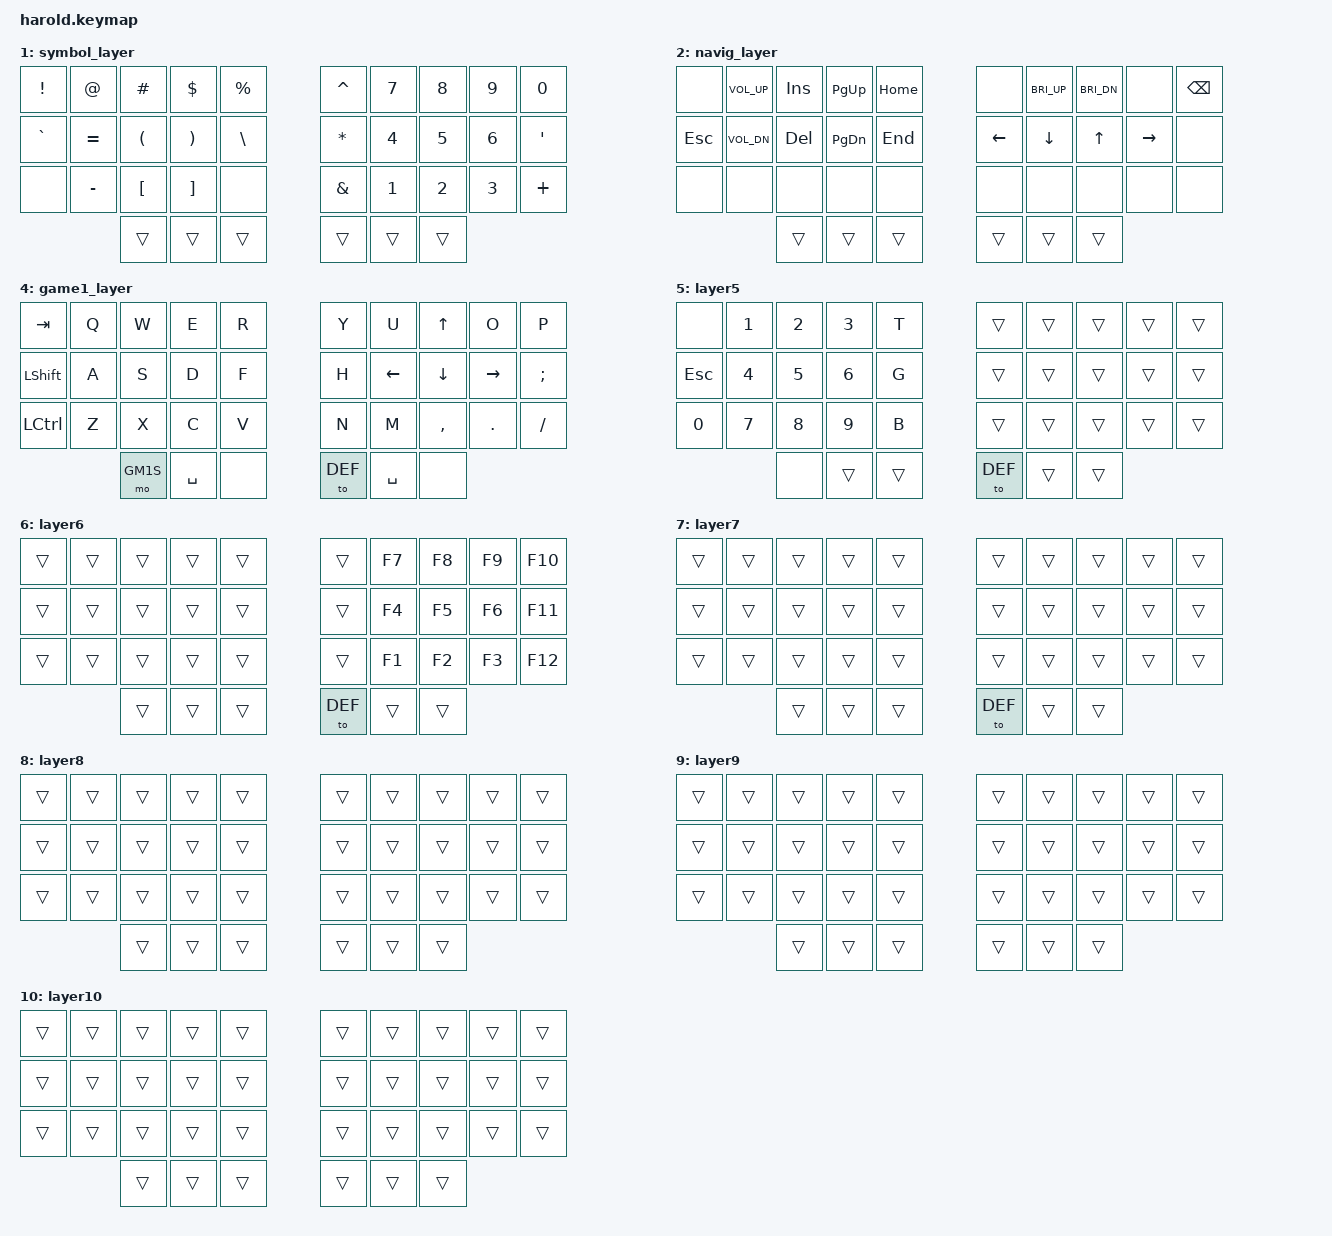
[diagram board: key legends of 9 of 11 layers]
// Copyright (c) 2022 The ZMK Contributors
// SPDX-License-Identifier: MIT

#include <behaviors.dtsi>
#include <dt-bindings/zmk/keys.h>
#include <dt-bindings/zmk/bt.h>

// Home row mods macro
#define HRML(k1,k2) &ht LALT  k1  &ht LCTRL k2
#define HRMR(k1,k2) &ht RCTRL k1  &ht RALT  k2

#define HTWN(k1)    &htwin LGUI k1

// Bluetooth Profile Selection shortcut
#define BTSL(X)      &bt BT_SEL X

// Some handy aliases
#define WQUIT        LA(F4)     // Windows Quit
#define TMUX_MOD     LC(SPACE)  // TMUX Modifier

// Layer Mnemonics
#define DEF   0   // Default
#define SYM   1   // Symbols
#define NAV   2   // Navigation + Media
#define CFG   3   // Misc/Settings
#define GM1   4   // Gaming 1
#define GM1S  5   // Gaming 1 Super-Layer
#define FKEY  6   // F-Key layer, OneShot w/ Sticky Keys

// Emoji Key Defines

// Key positions (For combo keys etc)
//  ╭────┬────┬────┬────┬────╮   ╭────┬────┬────┬────┬────╮
//  │  0 │  1 │  2 │  3 │  4 │   │  5 │  6 │  7 │  8 │  9 │
//  ├────┼────┼────┼────┼────┤   ├────┼────┼────┼────┼────┤
//  │ 10 │ 11 │ 12 │ 13 │ 14 │   │ 15 │ 16 │ 17 │ 18 │ 19 │
//  ├────┼────┼────┼────┼────┤   ├────┼────┼────┼────┼────┤
//  │ 20 │ 21 │ 22 │ 23 │ 24 │   │ 25 │ 26 │ 27 │ 28 │ 29 │
//  ╰────┴────┼────┼────┼────┤   ├────┼────┼────┼────┴────╯
//            │ 30 │ 31 │ 32 │   │ 33 │ 34 │ 35 │
//            ╰────┴────┴────╯   ╰────┴────┴────╯

/ {
    combos {
        compatible = "zmk,combos";
        combo_game1 {
            timeout-ms = <50>;
            key-positions = <34 35>;
            bindings = <&to GM1>;
        };
    };

    behaviors {
        ht: hold_tap {
            label = "hold_tap";
            compatible = "zmk,behavior-hold-tap";
            #binding-cells = <2>;
            flavor = "balanced";
            tapping-term-ms = <350>;
            quick-tap-ms = <150>;
            global-quick-tap;
            bindings = <&kp>, <&kp>;
        };


        // Slower hold-tap for the windows key because it keeps triggering
        // So annoying ...
        htwin: hold_tap_win {
            label = "hold_tap_win";
            compatible = "zmk,behavior-hold-tap";
            #binding-cells = <2>;
            flavor = "balanced";

            tapping-term-ms = <400>;
            quick-tap-ms = <200>;
            global-quick-tap;
            bindings = <&kp>, <&kp>;
        };

        // TODO change this into some macro that sends
        // the tmux mode code (Ctrl+Spc) if it tap-held
        // for every subsequent key pressed
        td_tm: tmux_modifier {
            label = "tmux-tap-dance";
            compatible = "zmk,behavior-tap-dance";
            #binding-cells = <0>;
            bindings = <&mo NAV>, <&kp TMUX_MOD>;
        };

        td_cw: caps_word {
            label = "capsword-tap-dance";
            compatible = "zmk,behavior-tap-dance";
            #binding-cells = <0>;
            bindings = <&kp LSHIFT>, <&caps_word>;
        };
    };

    conditional_layers {
        compatible = "zmk,conditional-layers";
        tri_layer {
            if-layers = <SYM NAV>;
            then-layer = <CFG>;
        };
    };

    keymap {
        compatible = "zmk,keymap";
        // Layer 0
        // Note HomeRow Mods on Index/Middle finger for Ctrl/Alt respectively
        // Note Hold-Tap Win/Super key on pinky; originally on home row, but kept triggering
        default_layer {
            bindings = <
        //╭──────────┬──────────┬──────────┬──────────┬──────────╮   ╭──────────┬──────────┬──────────┬──────────┬──────────╮
        //│  Q       │  W       │  E       │  R       │  T       │   │  Y       │  U       │  I       │  O       │  P       │
            &kp Q      &kp W      &kp E      &kp R      &kp T          &kp Y      &kp U      &kp I      &kp O      &kp P
        //├──────────┼──────────┼──────────┼──────────┼──────────┤   ├──────────┼──────────┼──────────┼──────────┼──────────┤
        //│  A       │  S       │  D       │  F       │  G       │   │  H       │  J       │  K       │  L       │ ; :      │
            &kp A      &kp S     HRML(D,         F)     &kp G          &kp H      HRMR(J,        K)     &kp L      &kp SEMI
        //├──────────┼──────────┼──────────┼──────────┼──────────┤   ├──────────┼──────────┼──────────┼──────────┼──────────┤
        //│  Z       │  X       │  C       │  V       │  B       │   │  N       │  M       │ , <      │ . >      │ / ?      │
            HTWN(Z)    &kp X      &kp C      &kp V      &kp B          &kp N      &kp M      &kp COMMA  &kp DOT    HTWN(FSLH)
        //╰──────────┴──────────┼──────────┼──────────┼──────────┤   ├──────────┼──────────┼──────────┼──────────┴──────────╯
                                  &td_tm     &td_cw     &kp TAB        &kp RET    &kp SPACE  &mo SYM
        //                      ╰──────────┴──────────┴──────────╯   ╰──────────┴──────────┴──────────╯
            >;
        };

        // Layer 1: SYM
        symbol_layer {
            bindings = <
        //╭──────────┬──────────┬──────────┬──────────┬──────────╮   ╭──────────┬──────────┬──────────┬──────────┬──────────╮
        //│  !       │  @       │  #       │  $       │  %       │   │  ^       │  7       │  8       │  9       │  0       │
            &kp EXCL   &kp AT     &kp HASH   &kp DLLR   &kp PRCNT      &kp CARET  &kp N7     &kp N8     &kp N9     &kp N0
        //├──────────┼──────────┼──────────┼──────────┼──────────┤   ├──────────┼──────────┼──────────┼──────────┼──────────┤
        //│  `/~     │  =       │  (       │  )       │   \ |    │   │  *       │  4       │  5       │  6       │  ' "     │
            &kp GRAVE  &kp EQUAL  &kp LPAR   &kp RPAR   &kp BSLH       &kp STAR   &kp N4     &kp N5     &kp N6     &kp SQT
        //├──────────┼──────────┼──────────┼──────────┼──────────┤   ├──────────┼──────────┼──────────┼──────────┼──────────┤
        //│  (blank) │  - _     │  [ {     │  ] }     │          │   │  &       │  1       │  2       │  3       │  +       │
            &none      &kp MINUS  &kp LBKT   &kp RBKT   &none          &kp AMPS   &kp N1     &kp N2     &kp N3     &kp PLUS
        //╰──────────┴──────────┼──────────┼──────────┼──────────┤   ├──────────┼──────────┼──────────┼──────────┴──────────╯
                                  &trans     &trans     &trans         &trans     &trans     &trans
        //                      ╰──────────┴──────────┴──────────╯   ╰──────────┴──────────┴──────────╯
            >;
        };

        // Layer 2: NAV and Media
        navig_layer {
            bindings = <
        //╭──────────┬────────────┬──────────┬──────────┬──────────╮   ╭──────────┬───────────┬──────────┬──────────┬──────────╮
        //│          │  Vol+      │  Ins     │  PgUp    │  Home    │   │          │ Bright+   │ Bright-  │          │  BKSPACE │
            &none      &kp C_VOL_UP  &kp INS   &kp PG_UP  &kp HOME       &none      &kp C_BRI_UP &kp C_BRI_DN &none   &kp BSPC
        //├──────────┼────────────┼──────────┼──────────┼──────────┤   ├──────────┼───────────┼──────────┼──────────┼──────────┤
        //│  ESC     │  Vol-      │  Del     │  PgDn    │  End     │   │  LEFT    │  DOWN     │  UP      │  RIGHT   │          │
            &kp ESC    &kp C_VOL_DN &kp DEL    &kp PG_DN  &kp END        &kp LEFT   &kp DOWN    &kp UP     &kp RIGHT  &none     
        //├──────────┼────────────┼──────────┼──────────┼──────────┤   ├──────────┼───────────┼──────────┼──────────┼──────────┤
        //│          │            │          │          │          │   │          │           │          │          │          │
            &none      &none        &none      &none      &none          &none      &none       &none      &none      &none     
        //╰──────────┴────────────┼──────────┼──────────┼──────────┤   ├──────────┼───────────┼──────────┼──────────┴──────────╯
                                    &trans     &trans     &trans         &trans     &trans      &trans
        //                        ╰──────────┴──────────┴──────────╯   ╰──────────┴───────────┴──────────╯
            >;
        };

        // Layer 3: CFG layer
        config_layer {
            bindings = <
        //╭──────────┬────────────┬──────────┬──────────┬──────────╮   ╭──────────┬──────────┬──────────┬──────────┬──────────╮
        //│          │            │          │          │          │   │          │          │          │          │          │
            &bootloader &none       &none      &kp WQUIT   &none        &none      &none      &none      &none      &bootloader
        //├──────────┼────────────┼──────────┼──────────┼──────────┤   ├──────────┼──────────┼──────────┼──────────┼──────────┤
        //│          │            │          │          │          │   │          │          │          │          │          │
            &none      &to GM1      &sl FKEY   &none      &none          &none      BTSL(3)    BTSL(4)    &bt BT_CLR &none
        //├──────────┼────────────┼──────────┼──────────┼──────────┤   ├──────────┼──────────┼──────────┼──────────┼──────────┤
        //│          │            │          │          │          │   │          │          │          │          │          │
            &none      &none        &none      &none      &none          &none      BTSL(0)     BTSL(1)   BTSL(2)
        //╰──────────┴────────────┼──────────┼──────────┼──────────┤   ├──────────┼──────────┼──────────┼──────────┴──────────╯
                                    &trans     &trans     &trans         &trans     &trans     &trans
        //                        ╰──────────┴──────────┴──────────╯   ╰──────────┴──────────┴──────────╯
            >;
        };

        // Layer 4: GM1 (Gaming 1) Layer.
        //   It's QWERTY but shifted 1 to the right and includes TAB, Shift, and Ctrl keys
        game1_layer {
            bindings = <
        //╭────────────┬──────────┬──────────┬──────────┬──────────╮   ╭──────────┬──────────┬──────────┬──────────┬──────────╮
        //│   TAB      │ Q        │  W       │  E       │  R       │   │  Y       │  U       │  UP      │  O       │  P       │
            &kp TAB     &kp Q       &kp W      &kp E      &kp R          &kp Y      &kp U      &kp UP     &kp O      &kp P
        //├────────────┼──────────┼──────────┼──────────┼──────────┤   ├──────────┼──────────┼──────────┼──────────┼──────────┤
        //│  SHIFT     │ A        │  S       │  D       │  F       │   │  H       │  LEFT    │  DOWN    │  RIGHT   │ ; :      │
            &kp LSHIFT  &kp A       &kp S      &kp D      &kp F          &kp H      &kp LEFT   &kp DOWN   &kp RIGHT  &kp SEMI
        //├────────────┼──────────┼──────────┼──────────┼──────────┤   ├──────────┼──────────┼──────────┼──────────┼──────────┤
        //│  CTRL      │ Z        │  X       │  C       │  V       │   │  N       │  M       │ , <      │ . >      │ / ?      │
            &kp LCTRL   &kp Z       &kp X      &kp C      &kp V          &kp N      &kp M      &kp COMMA  &kp DOT    &kp FSLH
        //╰────────────┴──────────┼──────────┼──────────┼──────────┤   ├──────────┼──────────┼──────────┼──────────┴──────────╯
                                    &mo GM1S   &kp SPC    &none          &to DEF    &kp SPC    &none
        //                        ╰──────────┴──────────┴──────────╯   ╰──────────┴──────────┴──────────╯
            >;
        };

        // Layer 5: GM1S Gaming 1 Super-Layer
        //   Enables extra keys while within GM1 layer
        //   i.e. Number Keys, T/G/B keys etc
        layer5 {
            bindings = <
        //╭──────────┬────────────┬──────────┬──────────┬──────────╮   ╭──────────┬──────────┬──────────┬──────────┬──────────╮
        //│          │      1     │      2   │      3   │     T    │   │          │          │          │          │          │
            &none      &kp N1       &kp N2     &kp N3     &kp T          &trans     &trans     &trans     &trans     &trans
        //├──────────┼────────────┼──────────┼──────────┼──────────┤   ├──────────┼──────────┼──────────┼──────────┼──────────┤
        //│          │      4     │      5   │      6   │     G    │   │          │          │          │          │          │
            &kp ESC    &kp N4       &kp N5     &kp N6     &kp G          &trans     &trans     &trans     &trans     &trans
        //├──────────┼────────────┼──────────┼──────────┼──────────┤   ├──────────┼──────────┼──────────┼──────────┼──────────┤
        //│      0   │      7     │      8   │      9   │     B    │   │          │          │          │          │          │
            &kp N0     &kp N7       &kp N8     &kp N9     &kp B          &trans     &trans     &trans     &trans     &trans
        //╰──────────┴────────────┼──────────┼──────────┼──────────┤   ├──────────┼──────────┼──────────┼──────────┴──────────╯
                                    &none      &trans     &trans         &to DEF    &trans     &trans
        //                        ╰──────────┴──────────┴──────────╯   ╰──────────┴──────────┴──────────╯
            >;
        };

        // Layer 6: FKEY Layer (One-Shot)
        //          At the moment, F-Keys CANNOT be combined with other combinations ...
        //          Maybe I'll fix the keymap to support that eventually
        layer6 {
            bindings = <
        //╭──────────┬────────────┬──────────┬──────────┬──────────╮   ╭──────────┬──────────┬──────────┬──────────┬──────────╮
        //│          │            │          │          │          │   │          │  F7      │  F8      │  F9      │  F10     │
            &trans     &trans       &trans     &trans     &trans         &trans     &kp F7     &kp F8     &kp F9     &kp F10
        //├──────────┼────────────┼──────────┼──────────┼──────────┤   ├──────────┼──────────┼──────────┼──────────┼──────────┤
        //│          │            │          │          │          │   │          │  F4      │  F5      │  F6      │  F11     │
            &trans     &trans       &trans     &trans     &trans         &trans     &kp F4     &kp F5     &kp F6     &kp F11
        //├──────────┼────────────┼──────────┼──────────┼──────────┤   ├──────────┼──────────┼──────────┼──────────┼──────────┤
        //│          │            │          │          │          │   │          │  F1      │  F2      │  F3      │  F12     │
            &trans     &trans       &trans     &trans     &trans         &trans     &kp F1     &kp F2     &kp F3     &kp F12
        //╰──────────┴────────────┼──────────┼──────────┼──────────┤   ├──────────┼──────────┼──────────┼──────────┴──────────╯
                                    &trans     &trans     &trans         &to DEF    &trans     &trans
        //                        ╰──────────┴──────────┴──────────╯   ╰──────────┴──────────┴──────────╯
            >;
        };

        // Layer 7: TBD
        layer7 {
            bindings = <
        //╭──────────┬────────────┬──────────┬──────────┬──────────╮   ╭──────────┬──────────┬──────────┬──────────┬──────────╮
        //│          │            │          │          │          │   │          │          │          │          │          │
            &trans     &trans       &trans     &trans     &trans         &trans     &trans     &trans     &trans     &trans
        //├──────────┼────────────┼──────────┼──────────┼──────────┤   ├──────────┼──────────┼──────────┼──────────┼──────────┤
        //│          │            │          │          │          │   │          │          │          │          │          │
            &trans     &trans       &trans     &trans     &trans         &trans     &trans     &trans     &trans     &trans
        //├──────────┼────────────┼──────────┼──────────┼──────────┤   ├──────────┼──────────┼──────────┼──────────┼──────────┤
        //│          │            │          │          │          │   │          │          │          │          │          │
            &trans     &trans       &trans     &trans     &trans         &trans     &trans     &trans     &trans     &trans
        //╰──────────┴────────────┼──────────┼──────────┼──────────┤   ├──────────┼──────────┼──────────┼──────────┴──────────╯
                                    &trans     &trans     &trans         &to DEF    &trans     &trans
        //                        ╰──────────┴──────────┴──────────╯   ╰──────────┴──────────┴──────────╯
            >;
        };

        // Layer 8: TBD
        layer8 {
            bindings = <
        //╭──────────┬────────────┬──────────┬──────────┬──────────╮   ╭──────────┬──────────┬──────────┬──────────┬──────────╮
        //│          │            │          │          │          │   │          │          │          │          │          │
            &trans     &trans       &trans     &trans     &trans         &trans     &trans     &trans     &trans     &trans
        //├──────────┼────────────┼──────────┼──────────┼──────────┤   ├──────────┼──────────┼──────────┼──────────┼──────────┤
        //│          │            │          │          │          │   │          │          │          │          │          │
            &trans     &trans       &trans     &trans     &trans         &trans     &trans     &trans     &trans     &trans
        //├──────────┼────────────┼──────────┼──────────┼──────────┤   ├──────────┼──────────┼──────────┼──────────┼──────────┤
        //│          │            │          │          │          │   │          │          │          │          │          │
            &trans     &trans       &trans     &trans     &trans         &trans     &trans     &trans     &trans     &trans
        //╰──────────┴────────────┼──────────┼──────────┼──────────┤   ├──────────┼──────────┼──────────┼──────────┴──────────╯
                                    &trans     &trans     &trans         &trans     &trans     &trans
        //                        ╰──────────┴──────────┴──────────╯   ╰──────────┴──────────┴──────────╯
            >;
        };

        // Layer 9: TBD
        layer9 {
            bindings = <
        //╭──────────┬────────────┬──────────┬──────────┬──────────╮   ╭──────────┬──────────┬──────────┬──────────┬──────────╮
        //│          │            │          │          │          │   │          │          │          │          │          │
            &trans     &trans       &trans     &trans     &trans         &trans     &trans     &trans     &trans     &trans
        //├──────────┼────────────┼──────────┼──────────┼──────────┤   ├──────────┼──────────┼──────────┼──────────┼──────────┤
        //│          │            │          │          │          │   │          │          │          │          │          │
            &trans     &trans       &trans     &trans     &trans         &trans     &trans     &trans     &trans     &trans
        //├──────────┼────────────┼──────────┼──────────┼──────────┤   ├──────────┼──────────┼──────────┼──────────┼──────────┤
        //│          │            │          │          │          │   │          │          │          │          │          │
            &trans     &trans       &trans     &trans     &trans         &trans     &trans     &trans     &trans     &trans
        //╰──────────┴────────────┼──────────┼──────────┼──────────┤   ├──────────┼──────────┼──────────┼──────────┴──────────╯
                                    &trans     &trans     &trans         &trans     &trans     &trans
        //                        ╰──────────┴──────────┴──────────╯   ╰──────────┴──────────┴──────────╯
            >;
        };

        // Layer 10: TBD
        layer10 {
            bindings = <
        //╭──────────┬────────────┬──────────┬──────────┬──────────╮   ╭──────────┬──────────┬──────────┬──────────┬──────────╮
        //│          │            │          │          │          │   │          │          │          │          │          │
            &trans     &trans       &trans     &trans     &trans         &trans     &trans     &trans     &trans     &trans
        //├──────────┼────────────┼──────────┼──────────┼──────────┤   ├──────────┼──────────┼──────────┼──────────┼──────────┤
        //│          │            │          │          │          │   │          │          │          │          │          │
            &trans     &trans       &trans     &trans     &trans         &trans     &trans     &trans     &trans     &trans
        //├──────────┼────────────┼──────────┼──────────┼──────────┤   ├──────────┼──────────┼──────────┼──────────┼──────────┤
        //│          │            │          │          │          │   │          │          │          │          │          │
            &trans     &trans       &trans     &trans     &trans         &trans     &trans     &trans     &trans     &trans
        //╰──────────┴────────────┼──────────┼──────────┼──────────┤   ├──────────┼──────────┼──────────┼──────────┴──────────╯
                                    &trans     &trans     &trans         &trans     &trans     &trans
        //                        ╰──────────┴──────────┴──────────╯   ╰──────────┴──────────┴──────────╯
            >;
        };
    };
};
